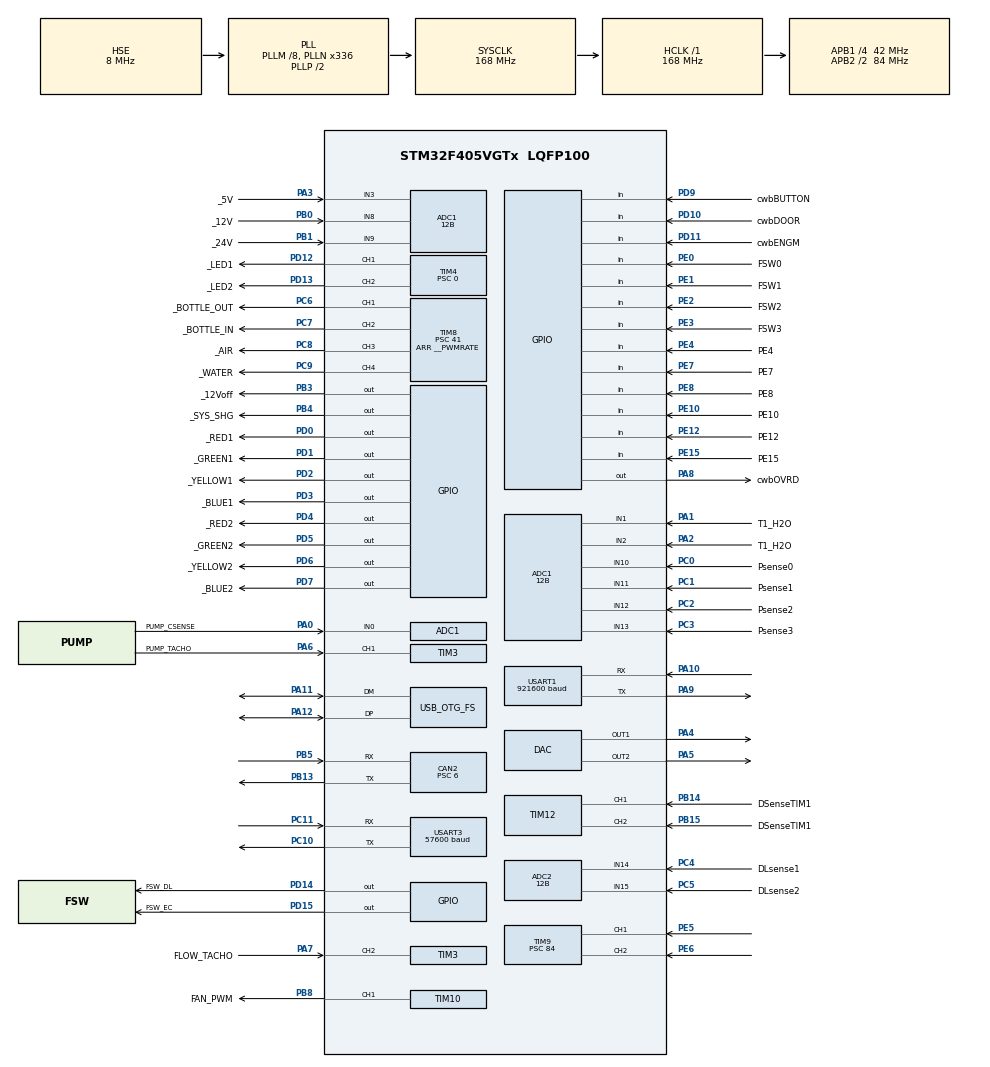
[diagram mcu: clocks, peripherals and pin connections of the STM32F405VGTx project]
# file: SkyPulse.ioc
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ADC1.Channel-0\#ChannelRegularConversion=ADC_CHANNEL_0
ADC1.Channel-1\#ChannelRegularConversion=ADC_CHANNEL_1
ADC1.Channel-2\#ChannelRegularConversion=ADC_CHANNEL_2
ADC1.Channel-3\#ChannelRegularConversion=ADC_CHANNEL_3
ADC1.Channel-4\#ChannelRegularConversion=ADC_CHANNEL_8
ADC1.Channel-5\#ChannelRegularConversion=ADC_CHANNEL_9
ADC1.Channel-6\#ChannelRegularConversion=ADC_CHANNEL_10
ADC1.Channel-7\#ChannelRegularConversion=ADC_CHANNEL_11
ADC1.Channel-8\#ChannelRegularConversion=ADC_CHANNEL_12
ADC1.Channel-9\#ChannelRegularConversion=ADC_CHANNEL_13
ADC1.ClockPrescaler=ADC_CLOCK_SYNC_PCLK_DIV4
ADC1.ContinuousConvMode=ENABLE
ADC1.DMAContinuousRequests=ENABLE
ADC1.DataAlign=ADC_DATAALIGN_RIGHT
ADC1.DiscontinuousConvMode=DISABLE
ADC1.EOCSelection=ADC_EOC_SEQ_CONV
ADC1.EnableAnalogWatchDog=false
ADC1.ExternalTrigConv=ADC_SOFTWARE_START
ADC1.ExternalTrigConvEdge=ADC_EXTERNALTRIGCONVEDGE_NONE
ADC1.InjNumberOfConversion=0
ADC1.NbrOfConversion=10
ADC1.NbrOfConversionFlag=1
ADC1.Rank-0\#ChannelRegularConversion=1
ADC1.Rank-1\#ChannelRegularConversion=2
ADC1.Rank-2\#ChannelRegularConversion=3
ADC1.Rank-3\#ChannelRegularConversion=4
ADC1.Rank-4\#ChannelRegularConversion=5
ADC1.Rank-5\#ChannelRegularConversion=6
ADC1.Rank-6\#ChannelRegularConversion=7
ADC1.Rank-7\#ChannelRegularConversion=8
ADC1.Rank-8\#ChannelRegularConversion=9
ADC1.Rank-9\#ChannelRegularConversion=10
ADC1.Resolution=ADC_RESOLUTION_12B
ADC1.SamplingTime-0\#ChannelRegularConversion=ADC_SAMPLETIME_84CYCLES
ADC1.SamplingTime-1\#ChannelRegularConversion=ADC_SAMPLETIME_84CYCLES
ADC1.SamplingTime-2\#ChannelRegularConversion=ADC_SAMPLETIME_84CYCLES
ADC1.SamplingTime-3\#ChannelRegularConversion=ADC_SAMPLETIME_84CYCLES
ADC1.SamplingTime-4\#ChannelRegularConversion=ADC_SAMPLETIME_84CYCLES
ADC1.SamplingTime-5\#ChannelRegularConversion=ADC_SAMPLETIME_84CYCLES
ADC1.SamplingTime-6\#ChannelRegularConversion=ADC_SAMPLETIME_84CYCLES
ADC1.SamplingTime-7\#ChannelRegularConversion=ADC_SAMPLETIME_84CYCLES
ADC1.SamplingTime-8\#ChannelRegularConversion=ADC_SAMPLETIME_84CYCLES
ADC1.SamplingTime-9\#ChannelRegularConversion=ADC_SAMPLETIME_84CYCLES
ADC1.ScanConvMode=ENABLE
ADC1.master=1
ADC2.Channel-0\#ChannelRegularConversion=ADC_CHANNEL_14
ADC2.Channel-1\#ChannelRegularConversion=ADC_CHANNEL_15
ADC2.ClockPrescaler=ADC_CLOCK_SYNC_PCLK_DIV4
ADC2.ContinuousConvMode=ENABLE
ADC2.DMAContinuousRequests=ENABLE
ADC2.DataAlign=ADC_DATAALIGN_RIGHT
ADC2.DiscontinuousConvMode=DISABLE
ADC2.EOCSelection=ADC_EOC_SEQ_CONV
ADC2.EnableAnalogWatchDog=false
ADC2.ExternalTrigConv=ADC_SOFTWARE_START
ADC2.ExternalTrigConvEdge=ADC_EXTERNALTRIGCONVEDGE_NONE
ADC2.InjNumberOfConversion=0
ADC2.NbrOfConversion=2
ADC2.NbrOfConversionFlag=1
ADC2.Rank-0\#ChannelRegularConversion=1
ADC2.Rank-1\#ChannelRegularConversion=2
ADC2.Resolution=ADC_RESOLUTION_12B
ADC2.SamplingTime-0\#ChannelRegularConversion=ADC_SAMPLETIME_56CYCLES
ADC2.SamplingTime-1\#ChannelRegularConversion=ADC_SAMPLETIME_56CYCLES
ADC2.ScanConvMode=ENABLE
CAN2.ABOM=ENABLE
CAN2.BS1=CAN_BS1_10TQ
CAN2.BS2=CAN_BS2_3TQ
CAN2.CalculateTimeBit=2000
CAN2.CalculateTimeQuantum=142.85714285714286
CAN2.Mode=CAN_MODE_NORMAL
CAN2.NART=ENABLE
CAN2.Prescaler=6
CAN2.SJW=CAN_SJW_4TQ
CAN2.TXFP=ENABLE
DAC.DAC_OutputBuffer2=DAC_OUTPUTBUFFER_ENABLE
DAC.DAC_Trigger=DAC_TRIGGER_T4_TRGO
Dma.ADC1.6.Direction=DMA_PERIPH_TO_MEMORY
Dma.ADC1.6.FIFOMode=DMA_FIFOMODE_DISABLE
Dma.ADC1.6.Instance=DMA2_Stream0
Dma.ADC1.6.MemDataAlignment=DMA_MDATAALIGN_HALFWORD
Dma.ADC1.6.MemInc=DMA_MINC_ENABLE
Dma.ADC1.6.Mode=DMA_CIRCULAR
Dma.ADC1.6.PeriphDataAlignment=DMA_PDATAALIGN_HALFWORD
Dma.ADC1.6.PeriphInc=DMA_PINC_DISABLE
Dma.ADC1.6.Priority=DMA_PRIORITY_LOW
Dma.ADC2.8.Direction=DMA_PERIPH_TO_MEMORY
Dma.ADC2.8.FIFOMode=DMA_FIFOMODE_DISABLE
Dma.ADC2.8.Instance=DMA2_Stream2
Dma.ADC2.8.MemDataAlignment=DMA_MDATAALIGN_HALFWORD
Dma.ADC2.8.MemInc=DMA_MINC_ENABLE
Dma.ADC2.8.Mode=DMA_CIRCULAR
Dma.ADC2.8.PeriphDataAlignment=DMA_PDATAALIGN_HALFWORD
Dma.ADC2.8.PeriphInc=DMA_PINC_DISABLE
Dma.ADC2.8.Priority=DMA_PRIORITY_LOW
Dma.DAC1.3.Direction=DMA_MEMORY_TO_PERIPH
Dma.DAC1.3.FIFOMode=DMA_FIFOMODE_ENABLE
Dma.DAC1.3.FIFOThreshold=DMA_FIFO_THRESHOLD_FULL
Dma.DAC1.3.Instance=DMA1_Stream5
Dma.DAC1.3.MemBurst=DMA_MBURST_SINGLE
Dma.DAC1.3.MemDataAlignment=DMA_MDATAALIGN_HALFWORD
Dma.DAC1.3.MemInc=DMA_MINC_ENABLE
Dma.DAC1.3.Mode=DMA_CIRCULAR
Dma.DAC1.3.PeriphBurst=DMA_PBURST_SINGLE
Dma.DAC1.3.PeriphDataAlignment=DMA_PDATAALIGN_HALFWORD
Dma.DAC1.3.PeriphInc=DMA_PINC_DISABLE
Dma.DAC1.3.Priority=DMA_PRIORITY_LOW
Dma.Request0=USART3_RX
Dma.Request1=USART3_TX
Dma.Request2=TIM4_UP
Dma.Request3=DAC1
Dma.Request4=USART1_RX
Dma.Request5=USART1_TX
Dma.Request6=ADC1
Dma.Request7=TIM8_UP
Dma.Request8=ADC2
Dma.TIM4_UP.2.Direction=DMA_MEMORY_TO_PERIPH
Dma.TIM4_UP.2.FIFOMode=DMA_FIFOMODE_ENABLE
Dma.TIM4_UP.2.FIFOThreshold=DMA_FIFO_THRESHOLD_FULL
Dma.TIM4_UP.2.Instance=DMA1_Stream6
Dma.TIM4_UP.2.MemBurst=DMA_MBURST_SINGLE
Dma.TIM4_UP.2.MemDataAlignment=DMA_MDATAALIGN_BYTE
Dma.TIM4_UP.2.MemInc=DMA_MINC_ENABLE
Dma.TIM4_UP.2.Mode=DMA_NORMAL
Dma.TIM4_UP.2.PeriphBurst=DMA_PBURST_SINGLE
Dma.TIM4_UP.2.PeriphDataAlignment=DMA_PDATAALIGN_HALFWORD
Dma.TIM4_UP.2.PeriphInc=DMA_PINC_DISABLE
Dma.TIM4_UP.2.Priority=DMA_PRIORITY_LOW
Dma.TIM8_UP.7.Direction=DMA_MEMORY_TO_PERIPH
Dma.TIM8_UP.7.FIFOMode=DMA_FIFOMODE_ENABLE
Dma.TIM8_UP.7.FIFOThreshold=DMA_FIFO_THRESHOLD_FULL
Dma.TIM8_UP.7.Instance=DMA2_Stream1
Dma.TIM8_UP.7.MemBurst=DMA_MBURST_SINGLE
Dma.TIM8_UP.7.MemDataAlignment=DMA_MDATAALIGN_WORD
Dma.TIM8_UP.7.MemInc=DMA_MINC_ENABLE
Dma.TIM8_UP.7.Mode=DMA_CIRCULAR
Dma.TIM8_UP.7.PeriphBurst=DMA_PBURST_SINGLE
Dma.TIM8_UP.7.PeriphDataAlignment=DMA_PDATAALIGN_HALFWORD
Dma.TIM8_UP.7.PeriphInc=DMA_PINC_DISABLE
Dma.TIM8_UP.7.Priority=DMA_PRIORITY_LOW
Dma.USART1_RX.4.Direction=DMA_PERIPH_TO_MEMORY
Dma.USART1_RX.4.FIFOMode=DMA_FIFOMODE_DISABLE
Dma.USART1_RX.4.Instance=DMA2_Stream5
Dma.USART1_RX.4.MemDataAlignment=DMA_MDATAALIGN_BYTE
Dma.USART1_RX.4.MemInc=DMA_MINC_ENABLE
Dma.USART1_RX.4.Mode=DMA_CIRCULAR
Dma.USART1_RX.4.PeriphDataAlignment=DMA_PDATAALIGN_BYTE
Dma.USART1_RX.4.PeriphInc=DMA_PINC_DISABLE
Dma.USART1_RX.4.Priority=DMA_PRIORITY_LOW
Dma.USART1_TX.5.Direction=DMA_MEMORY_TO_PERIPH
Dma.USART1_TX.5.FIFOMode=DMA_FIFOMODE_DISABLE
Dma.USART1_TX.5.Instance=DMA2_Stream7
Dma.USART1_TX.5.MemDataAlignment=DMA_MDATAALIGN_BYTE
Dma.USART1_TX.5.MemInc=DMA_MINC_ENABLE
Dma.USART1_TX.5.Mode=DMA_NORMAL
Dma.USART1_TX.5.PeriphDataAlignment=DMA_PDATAALIGN_BYTE
Dma.USART1_TX.5.PeriphInc=DMA_PINC_DISABLE
Dma.USART1_TX.5.Priority=DMA_PRIORITY_LOW
Dma.USART3_RX.0.Direction=DMA_PERIPH_TO_MEMORY
Dma.USART3_RX.0.FIFOMode=DMA_FIFOMODE_DISABLE
Dma.USART3_RX.0.Instance=DMA1_Stream1
Dma.USART3_RX.0.MemDataAlignment=DMA_MDATAALIGN_BYTE
Dma.USART3_RX.0.MemInc=DMA_MINC_ENABLE
Dma.USART3_RX.0.Mode=DMA_CIRCULAR
Dma.USART3_RX.0.PeriphDataAlignment=DMA_PDATAALIGN_BYTE
Dma.USART3_RX.0.PeriphInc=DMA_PINC_DISABLE
Dma.USART3_RX.0.Priority=DMA_PRIORITY_LOW
Dma.USART3_TX.1.Direction=DMA_MEMORY_TO_PERIPH
Dma.USART3_TX.1.FIFOMode=DMA_FIFOMODE_DISABLE
Dma.USART3_TX.1.Instance=DMA1_Stream3
Dma.USART3_TX.1.MemDataAlignment=DMA_MDATAALIGN_BYTE
Dma.USART3_TX.1.MemInc=DMA_MINC_ENABLE
Dma.USART3_TX.1.Mode=DMA_NORMAL
Dma.USART3_TX.1.PeriphDataAlignment=DMA_PDATAALIGN_BYTE
Dma.USART3_TX.1.PeriphInc=DMA_PINC_DISABLE
Dma.USART3_TX.1.Priority=DMA_PRIORITY_LOW
FATFS._FS_LOCK=5
FATFS._FS_RPATH=2
FATFS._USE_FIND=1
FATFS._USE_LFN=2
FATFS._VOLUMES=1
FREERTOS.HEAP_NUMBER=2
FREERTOS.Tasks01=defaultTask,0,512,StartDefaultTask,Default,NULL,Dynamic,NULL,NULL
FREERTOS.configCHECK_FOR_STACK_OVERFLOW=2
FREERTOS.configTOTAL_HEAP_SIZE=0x10000
FREERTOS.configUSE_MALLOC_FAILED_HOOK=1
IWDG.Prescaler=IWDG_PRESCALER_32
IWDG.Reload=400
Mcu.Family=STM32F4
Mcu.Name=STM32F405VGTx
Mcu.Package=LQFP100
Mcu.UserConstants=__RXLEN,128;__TXLEN,128;__CMDLEN,128;__PWMRATE,2000;__VALVES,4;__LEDS,80;__TH,94;__TL,36;__TP,130;SW_version,106
NVIC.CAN2_RX0_IRQn=true\:5\:0\:false\:false\:true\:true\:true\:true
NVIC.CAN2_SCE_IRQn=true\:5\:0\:false\:false\:true\:true\:true\:true
NVIC.CAN2_TX_IRQn=true\:5\:0\:false\:false\:true\:true\:true\:true
NVIC.DMA1_Stream1_IRQn=true\:5\:0\:false\:false\:true\:true\:true\:true
NVIC.DMA1_Stream3_IRQn=true\:5\:0\:false\:false\:true\:true\:true\:true
NVIC.DMA1_Stream5_IRQn=true\:5\:0\:false\:false\:true\:true\:false\:true
NVIC.DMA1_Stream6_IRQn=true\:5\:0\:false\:false\:true\:true\:false\:true
NVIC.DMA2_Stream0_IRQn=true\:5\:0\:false\:false\:true\:true\:false\:true
NVIC.DMA2_Stream1_IRQn=true\:5\:0\:false\:false\:true\:true\:false\:true
NVIC.DMA2_Stream2_IRQn=true\:5\:0\:false\:false\:true\:true\:false\:true
NVIC.DMA2_Stream5_IRQn=true\:5\:0\:false\:false\:true\:true\:false\:true
NVIC.DMA2_Stream7_IRQn=true\:5\:0\:false\:false\:true\:true\:true\:true
NVIC.OTG_FS_IRQn=true\:5\:0\:false\:false\:true\:true\:true\:true
NVIC.PriorityGroup=NVIC_PRIORITYGROUP_4
NVIC.TIM1_BRK_TIM9_IRQn=true\:5\:0\:false\:false\:true\:true\:true\:true
NVIC.TIM2_IRQn=true\:0\:0\:false\:false\:true\:false\:false\:true
NVIC.TIM3_IRQn=true\:5\:0\:false\:false\:true\:true\:true\:true
NVIC.TimeBase=TIM2_IRQn
NVIC.TimeBaseIP=TIM2
NVIC.USART1_IRQn=true\:5\:0\:false\:false\:true\:true\:true\:true
NVIC.USART3_IRQn=true\:5\:0\:false\:false\:true\:true\:true\:true
PA0-WKUP.GPIO_Label=PUMP_CSENSE
PA0-WKUP.Signal=ADCx_IN0
PA1.GPIO_Label=T1_H2O
PA1.Signal=ADCx_IN1
PA10.Mode=Asynchronous
PA10.Signal=USART1_RX
PA11.GPIO_PuPd=GPIO_PULLDOWN
PA11.Mode=Device_Only
PA11.Signal=USB_OTG_FS_DM
PA12.GPIO_PuPd=GPIO_PULLDOWN
PA12.Mode=Device_Only
PA12.Signal=USB_OTG_FS_DP
PA13.Mode=Serial_Wire
PA13.Signal=SYS_JTMS-SWDIO
PA14.Mode=Serial_Wire
PA14.Signal=SYS_JTCK-SWCLK
PA2.GPIO_Label=T1_H2O
PA2.Signal=ADCx_IN2
PA3.GPIO_Label=_5V
PA3.Signal=ADCx_IN3
PA4.Signal=COMP_DAC1_group
PA5.Signal=COMP_DAC2_group
PA6.GPIO_Label=PUMP_TACHO
PA6.GPIO_PuPd=GPIO_PULLUP
PA6.Signal=S_TIM3_CH1
PA7.GPIO_Label=FLOW_TACHO
PA7.GPIO_PuPd=GPIO_PULLUP
PA7.Signal=S_TIM3_CH2
PA8.GPIO_Label=cwbOVRD
PA8.GPIO_ModeDefaultOutputPP=GPIO_MODE_OUTPUT_OD
PA8.PinState=GPIO_PIN_SET
PA8.Signal=GPIO_Output
PA9.Mode=Asynchronous
PA9.Signal=USART1_TX
PB0.GPIO_Label=_12V
PB0.Signal=ADCx_IN8
PB1.GPIO_Label=_24V
PB1.Signal=ADCx_IN9
PB13.GPIO_PuPd=GPIO_PULLUP
PB13.Mode=Slave
PB13.Signal=CAN2_TX
PB14.GPIO_Label=DSenseTIM1
PB14.GPIO_PuPd=GPIO_PULLDOWN
PB14.GPIO_Speed=GPIO_SPEED_FREQ_MEDIUM
PB14.Signal=S_TIM12_CH1
PB15.GPIO_Label=DSenseTIM1
PB15.GPIO_PuPd=GPIO_PULLDOWN
PB15.GPIO_Speed=GPIO_SPEED_FREQ_MEDIUM
PB15.Signal=S_TIM12_CH2
PB3.GPIO_Label=_12Voff
PB3.Signal=GPIO_Output
PB4.GPIO_Label=_SYS_SHG
PB4.GPIO_ModeDefaultOutputPP=GPIO_MODE_OUTPUT_OD
PB4.PinState=GPIO_PIN_RESET
PB4.Signal=GPIO_Output
PB5.GPIO_PuPd=GPIO_PULLUP
PB5.Mode=Slave
PB5.Signal=CAN2_RX
PB8.GPIO_Label=FAN_PWM
PB8.GPIO_Speed=GPIO_SPEED_FREQ_HIGH
PB8.Signal=S_TIM10_CH1
PC0.GPIO_Label=Psense0
PC0.Signal=ADCx_IN10
PC1.GPIO_Label=Psense1
PC1.Signal=ADCx_IN11
PC10.Mode=Asynchronous
PC10.Signal=USART3_TX
PC11.Mode=Asynchronous
PC11.Signal=USART3_RX
PC14-OSC32_IN.Mode=LSE-External-Oscillator
PC14-OSC32_IN.Signal=RCC_OSC32_IN
PC15-OSC32_OUT.Mode=LSE-External-Oscillator
PC15-OSC32_OUT.Signal=RCC_OSC32_OUT
PC2.GPIO_Label=Psense2
PC2.Signal=ADCx_IN12
PC3.GPIO_Label=Psense3
PC3.Signal=ADCx_IN13
PC4.GPIO_Label=DLsense1
PC4.Signal=ADCx_IN14
PC5.GPIO_Label=DLsense2
PC5.GPIO_PuPd=GPIO_NOPULL
PC5.Signal=ADCx_IN15
PC6.GPIO_Label=_BOTTLE_OUT
PC6.GPIO_Speed=GPIO_SPEED_FREQ_HIGH
PC6.Signal=S_TIM8_CH1
PC7.GPIO_Label=_BOTTLE_IN
PC7.GPIO_Speed=GPIO_SPEED_FREQ_HIGH
PC7.Signal=S_TIM8_CH2
PC8.GPIO_Label=_AIR
PC8.GPIO_Speed=GPIO_SPEED_FREQ_HIGH
PC8.Signal=S_TIM8_CH3
PC9.GPIO_Label=_WATER
PC9.GPIO_Speed=GPIO_SPEED_FREQ_HIGH
PC9.Signal=S_TIM8_CH4
PD0.GPIO_Label=_RED1
PD0.GPIO_ModeDefaultOutputPP=GPIO_MODE_OUTPUT_OD
PD0.GPIO_PuPd=GPIO_NOPULL
PD0.PinState=GPIO_PIN_SET
PD0.Signal=GPIO_Output
PD1.GPIO_Label=_GREEN1
PD1.GPIO_ModeDefaultOutputPP=GPIO_MODE_OUTPUT_OD
PD1.GPIO_PuPd=GPIO_NOPULL
PD1.PinState=GPIO_PIN_SET
PD1.Signal=GPIO_Output
PD10.GPIO_Label=cwbDOOR
PD10.GPIO_PuPd=GPIO_PULLDOWN
PD10.Signal=GPIO_Input
PD11.GPIO_Label=cwbENGM
PD11.GPIO_PuPd=GPIO_PULLDOWN
PD11.Signal=GPIO_Input
PD12.GPIO_Label=_LED1
PD12.GPIO_ModeDefaultPP=GPIO_MODE_AF_OD
PD12.GPIO_PuPd=GPIO_PULLUP
PD12.GPIO_Speed=GPIO_SPEED_FREQ_VERY_HIGH
PD12.Signal=S_TIM4_CH1
PD13.GPIO_Label=_LED2
PD13.GPIO_ModeDefaultPP=GPIO_MODE_AF_OD
PD13.GPIO_PuPd=GPIO_PULLUP
PD13.GPIO_Speed=GPIO_SPEED_FREQ_VERY_HIGH
PD13.Signal=S_TIM4_CH2
PD14.GPIO_Label=FSW_DL
PD14.GPIO_ModeDefaultOutputPP=GPIO_MODE_OUTPUT_OD
PD14.PinState=GPIO_PIN_SET
PD14.Signal=GPIO_Output
PD15.GPIO_Label=FSW_EC
PD15.GPIO_ModeDefaultOutputPP=GPIO_MODE_OUTPUT_OD
PD15.PinState=GPIO_PIN_SET
PD15.Signal=GPIO_Output
PD2.GPIO_Label=_YELLOW1
PD2.GPIO_ModeDefaultOutputPP=GPIO_MODE_OUTPUT_OD
PD2.GPIO_PuPd=GPIO_NOPULL
PD2.PinState=GPIO_PIN_SET
PD2.Signal=GPIO_Output
PD3.GPIO_Label=_BLUE1
PD3.GPIO_ModeDefaultOutputPP=GPIO_MODE_OUTPUT_OD
PD3.GPIO_PuPd=GPIO_NOPULL
PD3.PinState=GPIO_PIN_SET
PD3.Signal=GPIO_Output
PD4.GPIO_Label=_RED2
PD4.GPIO_ModeDefaultOutputPP=GPIO_MODE_OUTPUT_OD
PD4.GPIO_PuPd=GPIO_NOPULL
PD4.PinState=GPIO_PIN_SET
PD4.Signal=GPIO_Output
PD5.GPIO_Label=_GREEN2
PD5.GPIO_ModeDefaultOutputPP=GPIO_MODE_OUTPUT_OD
PD5.GPIO_PuPd=GPIO_NOPULL
PD5.PinState=GPIO_PIN_SET
PD5.Signal=GPIO_Output
PD6.GPIO_Label=_YELLOW2
PD6.GPIO_ModeDefaultOutputPP=GPIO_MODE_OUTPUT_OD
PD6.GPIO_PuPd=GPIO_NOPULL
PD6.PinState=GPIO_PIN_SET
PD6.Signal=GPIO_Output
PD7.GPIO_Label=_BLUE2
PD7.GPIO_ModeDefaultOutputPP=GPIO_MODE_OUTPUT_OD
PD7.GPIO_PuPd=GPIO_NOPULL
PD7.PinState=GPIO_PIN_SET
PD7.Signal=GPIO_Output
PD9.GPIO_Label=cwbBUTTON
PD9.GPIO_PuPd=GPIO_PULLDOWN
PD9.Signal=GPIO_Input
PE0.GPIO_Label=FSW0
PE0.GPIO_PuPd=GPIO_PULLUP
PE0.Signal=GPIO_Input
PE1.GPIO_Label=FSW1
PE1.GPIO_PuPd=GPIO_PULLUP
PE1.Signal=GPIO_Input
PE10.GPIO_Label=PE10
PE10.GPIO_PuPd=GPIO_PULLUP
PE10.Signal=GPIO_Input
PE12.GPIO_Label=PE12
PE12.GPIO_PuPd=GPIO_PULLUP
PE12.Signal=GPIO_Input
PE15.GPIO_Label=PE15
PE15.GPIO_PuPd=GPIO_PULLUP
PE15.Signal=GPIO_Input
PE2.GPIO_Label=FSW2
PE2.GPIO_PuPd=GPIO_PULLUP
PE2.Signal=GPIO_Input
PE3.GPIO_Label=FSW3
PE3.GPIO_PuPd=GPIO_PULLUP
PE3.Signal=GPIO_Input
PE4.GPIO_Label=PE4
PE4.GPIO_PuPd=GPIO_PULLUP
PE4.Signal=GPIO_Input
PE5.GPIO_PuPd=GPIO_PULLUP
PE5.Signal=S_TIM9_CH1
PE6.GPIO_PuPd=GPIO_PULLUP
PE6.Signal=S_TIM9_CH2
PE7.GPIO_Label=PE7
PE7.GPIO_PuPd=GPIO_PULLUP
PE7.Signal=GPIO_Input
PE8.GPIO_Label=PE8
PE8.GPIO_PuPd=GPIO_PULLUP
PE8.Signal=GPIO_Input
PH0-OSC_IN.Mode=HSE-External-Oscillator
PH0-OSC_IN.Signal=RCC_OSC_IN
PH1-OSC_OUT.Mode=HSE-External-Oscillator
PH1-OSC_OUT.Signal=RCC_OSC_OUT
ProjectManager.HeapSize=0x6000
ProjectManager.StackSize=0x2000
ProjectManager.TargetToolchain=MDK-ARM V5
RCC.48MHZClocksFreq_Value=48000000
RCC.AHBCLKDivider=RCC_SYSCLK_DIV1
RCC.AHBFreq_Value=168000000
RCC.APB1CLKDivider=RCC_HCLK_DIV4
RCC.APB1Freq_Value=42000000
RCC.APB1TimFreq_Value=84000000
RCC.APB2CLKDivider=RCC_HCLK_DIV2
RCC.APB2Freq_Value=84000000
RCC.APB2TimFreq_Value=168000000
RCC.CortexFreq_Value=168000000
RCC.HCLKFreq_Value=168000000
RCC.HSE_VALUE=8000000
RCC.HSI_VALUE=16000000
RCC.PLLM=8
RCC.PLLN=336
RCC.PLLQ=7
RCC.RCC_RTC_Clock_Source=RCC_RTCCLKSOURCE_LSI
RCC.RCC_RTC_Clock_SourceVirtual=RCC_RTCCLKSOURCE_LSE
RCC.SYSCLKFreq_VALUE=168000000
RCC.SYSCLKSource=RCC_SYSCLKSOURCE_PLLCLK
RCC.VCOOutputFreq_Value=336000000
RTC.Date=7
RTC.Format=RTC_FORMAT_BIN
RTC.Hours=15
RTC.Minutes=30
RTC.Month=RTC_MONTH_NOVEMBER
RTC.StoreOperation=RTC_STOREOPERATION_SET
RTC.WeekDay=RTC_WEEKDAY_TUESDAY
RTC.Year=17
SH.ADCx_IN0.0=ADC1_IN0,IN0
SH.ADCx_IN1.0=ADC1_IN1,IN1
SH.ADCx_IN10.0=ADC1_IN10,IN10
SH.ADCx_IN11.0=ADC1_IN11,IN11
SH.ADCx_IN12.0=ADC1_IN12,IN12
SH.ADCx_IN13.0=ADC1_IN13,IN13
SH.ADCx_IN14.0=ADC1_IN14
SH.ADCx_IN14.1=ADC2_IN14,IN14
SH.ADCx_IN15.0=ADC1_IN15
SH.ADCx_IN15.1=ADC2_IN15,IN15
SH.ADCx_IN2.0=ADC1_IN2,IN2
SH.ADCx_IN3.0=ADC1_IN3,IN3
SH.ADCx_IN8.0=ADC1_IN8,IN8
SH.ADCx_IN9.0=ADC1_IN9,IN9
SH.COMP_DAC1_group.0=DAC_OUT1,DAC_OUT1
SH.COMP_DAC2_group.0=DAC_OUT2,DAC_OUT2
SH.S_TIM10_CH1.0=TIM10_CH1,PWM Generation1 CH1
SH.S_TIM12_CH1.0=TIM12_CH1,Input_Capture1_from_TI1
SH.S_TIM12_CH2.0=TIM12_CH2,Input_Capture2_from_TI2
SH.S_TIM3_CH1.0=TIM3_CH1,Input_Capture1_from_TI1
SH.S_TIM3_CH2.0=TIM3_CH2,Input_Capture2_from_TI2
SH.S_TIM4_CH1.0=TIM4_CH1,PWM Generation1 CH1
SH.S_TIM4_CH2.0=TIM4_CH2,PWM Generation2 CH2
SH.S_TIM8_CH1.0=TIM8_CH1,PWM Generation1 CH1
SH.S_TIM8_CH2.0=TIM8_CH2,PWM Generation2 CH2
SH.S_TIM8_CH3.0=TIM8_CH3,PWM Generation3 CH3
SH.S_TIM8_CH4.0=TIM8_CH4,PWM Generation4 CH4
SH.S_TIM9_CH1.0=TIM9_CH1,Input_Capture1_from_TI1
SH.S_TIM9_CH2.0=TIM9_CH2,Input_Capture2_from_TI2
TIM10.Channel=TIM_CHANNEL_1
TIM10.Period=__PWMRATE
TIM10.Prescaler=29
TIM10.Pulse=10
TIM12.Channel-Input_Capture1_from_TI1=TIM_CHANNEL_1
TIM12.Channel-Input_Capture2_from_TI2=TIM_CHANNEL_2
TIM12.ICFilter_CH1=15
TIM12.ICFilter_CH2=15
TIM3.Channel-Input_Capture1_from_TI1=TIM_CHANNEL_1
TIM3.Channel-Input_Capture2_from_TI2=TIM_CHANNEL_2
TIM3.ICFilter_CH1=15
TIM3.ICFilter_CH2=15
TIM3.ICPolarity_CH1=TIM_INPUTCHANNELPOLARITY_BOTHEDGE
TIM3.ICPolarity_CH2=TIM_INPUTCHANNELPOLARITY_BOTHEDGE
TIM3.Prescaler=84
TIM4.Channel-PWM\ Generation1\ CH1=TIM_CHANNEL_1
TIM4.Channel-PWM\ Generation2\ CH2=TIM_CHANNEL_2
TIM4.CounterMode=TIM_COUNTERMODE_UP
TIM4.Period=__TP
TIM4.Prescaler=0
TIM4.TIM_MasterOutputTrigger=TIM_TRGO_UPDATE
TIM4.TIM_MasterSlaveMode=TIM_MASTERSLAVEMODE_ENABLE
TIM8.Channel-PWM\ Generation1\ CH1=TIM_CHANNEL_1
TIM8.Channel-PWM\ Generation2\ CH2=TIM_CHANNEL_2
TIM8.Channel-PWM\ Generation3\ CH3=TIM_CHANNEL_3
TIM8.Channel-PWM\ Generation4\ CH4=TIM_CHANNEL_4
TIM8.CounterMode=TIM_COUNTERMODE_CENTERALIGNED1
TIM8.Period=__PWMRATE
TIM8.Prescaler=41
TIM8.TIM_MasterOutputTrigger=TIM_TRGO_UPDATE
TIM8.TIM_MasterSlaveMode=TIM_MASTERSLAVEMODE_ENABLE
TIM9.Channel-Input_Capture1_from_TI1=TIM_CHANNEL_1
TIM9.Channel-Input_Capture2_from_TI2=TIM_CHANNEL_2
TIM9.ICFilter_CH1=15
TIM9.ICFilter_CH2=15
TIM9.ICPolarity_CH1=TIM_INPUTCHANNELPOLARITY_BOTHEDGE
TIM9.ICPolarity_CH2=TIM_INPUTCHANNELPOLARITY_BOTHEDGE
TIM9.Period=0xffff
TIM9.Prescaler=84
USART1.BaudRate=921600
USART1.HwFlowCtl-Asynchronous=UART_HWCONTROL_NONE
USART1.VirtualMode=VM_ASYNC
USART3.BaudRate=57600
USART3.VirtualMode=VM_ASYNC
USB_DEVICE.CLASS_NAME_FS=CDC
USB_DEVICE.VirtualMode-CDC_FS=Cdc
USB_DEVICE.VirtualModeFS=Cdc_FS
USB_OTG_FS.VirtualMode=Device_Only
USB_OTG_FS.dev_endpoints=4
USB_OTG_FS.vbus_sensing_enable=DISABLE
VP_CRC_VS_CRC.Mode=CRC_Activate
VP_FATFS_VS_Generic.Mode=User_defined
VP_FREERTOS_VS_CMSIS_V1.Mode=CMSIS_V1
VP_IWDG_VS_IWDG.Mode=IWDG_Activate
VP_RTC_VS_RTC_Activate.Mode=RTC_Enabled
VP_RTC_VS_RTC_Calendar.Mode=RTC_Calendar
VP_SYS_VS_tim2.Mode=TIM2
VP_TIM10_VS_ClockSourceINT.Mode=Enable_Timer
VP_TIM12_VS_ClockSourceINT.Mode=Internal
VP_TIM3_VS_ClockSourceINT.Mode=Internal
VP_TIM9_VS_ClockSourceINT.Mode=Internal
VP_USB_DEVICE_VS_USB_DEVICE_CDC_FS.Mode=CDC_FS
board=SkyPulse

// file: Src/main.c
/* USER CODE BEGIN Header */
/**
  ******************************************************************************
  * @file           : main.c
  * @brief          : Main program body
  ******************************************************************************
  * This notice applies to any and all portions of this file
  * that are not between comment pairs USER CODE BEGIN and
  * USER CODE END. Other portions of this file, whether
  * inserted by the user or by software development tools
  * are owned by their respective copyright owners.
  *
  * Copyright (c) 2019 STMicroelectronics International N.V.
  * All rights reserved.
  *
  * Redistribution and use in source and binary forms, with or without
  * modification, are permitted, provided that the following conditions are met:
  *
  * 1. Redistribution of source code must retain the above copyright notice,
  *    this list of conditions and the following disclaimer.
  * 2. Redistributions in binary form must reproduce the above copyright notice,
  *    this list of conditions and the following disclaimer in the documentation
  *    and/or other materials provided with the distribution.
  * 3. Neither the name of STMicroelectronics nor the names of other
  *    contributors to this software may be used to endorse or promote products
  *    derived from this software without specific written permission.
  * 4. This software, including modifications and/or derivative works of this
  *    software, must execute solely and exclusively on microcontroller or
  *    microprocessor devices manufactured by or for STMicroelectronics.
  * 5. Redistribution and use of this software other than as permitted under
  *    this license is void and will automatically terminate your rights under
  *    this license.
  *
  * THIS SOFTWARE IS PROVIDED BY STMICROELECTRONICS AND CONTRIBUTORS "AS IS"
  * AND ANY EXPRESS, IMPLIED OR STATUTORY WARRANTIES, INCLUDING, BUT NOT
  * LIMITED TO, THE IMPLIED WARRANTIES OF MERCHANTABILITY, FITNESS FOR A
  * PARTICULAR PURPOSE AND NON-INFRINGEMENT OF THIRD PARTY INTELLECTUAL PROPERTY
  * RIGHTS ARE DISCLAIMED TO THE FULLEST EXTENT PERMITTED BY LAW. IN NO EVENT
  * SHALL STMICROELECTRONICS OR CONTRIBUTORS BE LIABLE FOR ANY DIRECT, INDIRECT,
  * INCIDENTAL, SPECIAL, EXEMPLARY, OR CONSEQUENTIAL DAMAGES (INCLUDING, BUT NOT
  * LIMITED TO, PROCUREMENT OF SUBSTITUTE GOODS OR SERVICES; LOSS OF USE, DATA,
  * OR PROFITS; OR BUSINESS INTERRUPTION) HOWEVER CAUSED AND ON ANY THEORY OF
  * LIABILITY, WHETHER IN CONTRACT, STRICT LIABILITY, OR TORT (INCLUDING
  * NEGLIGENCE OR OTHERWISE) ARISING IN ANY WAY OUT OF THE USE OF THIS SOFTWARE,
  * EVEN IF ADVISED OF THE POSSIBILITY OF SUCH DAMAGE.
  *
  ******************************************************************************
  */
/* USER CODE END Header */
#include "main.h"
#include "cmsis_os.h"
#include "fatfs.h"
#include "usb_device.h"

/* USER CODE BEGIN Includes */
#include "misc.h"
/* USER CODE END Includes */

ADC_HandleTypeDef hadc1;
ADC_HandleTypeDef hadc2;
DMA_HandleTypeDef hdma_adc1;
DMA_HandleTypeDef hdma_adc2;

CAN_HandleTypeDef hcan2;

CRC_HandleTypeDef hcrc;

DAC_HandleTypeDef hdac;
DMA_HandleTypeDef hdma_dac1;

IWDG_HandleTypeDef hiwdg;

RTC_HandleTypeDef hrtc;

TIM_HandleTypeDef htim3;
TIM_HandleTypeDef htim4;
TIM_HandleTypeDef htim8;
TIM_HandleTypeDef htim9;
TIM_HandleTypeDef htim10;
TIM_HandleTypeDef htim12;
DMA_HandleTypeDef hdma_tim4_up;
DMA_HandleTypeDef hdma_tim8_up;

UART_HandleTypeDef huart1;
UART_HandleTypeDef huart3;
DMA_HandleTypeDef hdma_usart1_rx;
DMA_HandleTypeDef hdma_usart1_tx;
DMA_HandleTypeDef hdma_usart3_rx;
DMA_HandleTypeDef hdma_usart3_tx;

osThreadId defaultTaskHandle;
/* USER CODE BEGIN PV */
/* Private variables ---------------------------------------------------------*/
/* USER CODE END PV */

void SystemClock_Config(void);
static void MX_GPIO_Init(void);
static void MX_DMA_Init(void);
static void MX_ADC1_Init(void);
static void MX_DAC_Init(void);
static void MX_USART1_UART_Init(void);
static void MX_USART3_UART_Init(void);
static void MX_CAN2_Init(void);
static void MX_TIM10_Init(void);
static void MX_TIM9_Init(void);
static void MX_TIM3_Init(void);
static void MX_TIM8_Init(void);
static void MX_TIM4_Init(void);
static void MX_RTC_Init(void);
static void MX_ADC2_Init(void);
static void MX_IWDG_Init(void);
static void MX_CRC_Init(void);
static void MX_TIM12_Init(void);
void StartDefaultTask(void const * argument);

/* USER CODE BEGIN PFP */
/* Private function prototypes -----------------------------------------------*/
void makeIoc(void);																										// main app. C++ relay object
/* USER CODE END PFP */

/* USER CODE BEGIN 0 */
uint32_t	pumpTacho, fanTacho, flowTacho, valve_timeout[__VALVES];	// DMA memory registers..
uint16_t	pump_drive, fan_drive, valve_drive[__VALVES], led_drive[__LEDS*24+2];
_io				*canBuffer=NULL;
hwVersion	hw;
/* USER CODE END 0 */

int main(void)
{

  /* MCU Configuration--------------------------------------------------------*/

  /* Reset of all peripherals, Initializes the Flash interface and the Systick. */
  HAL_Init();

  /* Configure the system clock */
  SystemClock_Config();

  /* Initialize all configured peripherals */
  MX_GPIO_Init();
  MX_DMA_Init();
  MX_FATFS_Init();
  MX_ADC1_Init();
  MX_DAC_Init();
  MX_USART1_UART_Init();
  MX_USART3_UART_Init();
  MX_CAN2_Init();
  MX_TIM10_Init();
  MX_TIM9_Init();
  MX_TIM3_Init();
  MX_TIM8_Init();
  MX_TIM4_Init();
  MX_RTC_Init();
  MX_ADC2_Init();
  MX_IWDG_Init();
  MX_CRC_Init();
  MX_TIM12_Init();
  /* USER CODE BEGIN 2 */

	hw=(hwVersion)((~(HAL_GPIO_ReadPin(PE15_GPIO_Port, PE15_Pin) +
			2*(HAL_GPIO_ReadPin(PE12_GPIO_Port, PE12_Pin) +
				2*(HAL_GPIO_ReadPin(PE10_GPIO_Port, PE10_Pin) +
					2*(HAL_GPIO_ReadPin(PE8_GPIO_Port, PE8_Pin) +
						2*HAL_GPIO_ReadPin(PE7_GPIO_Port, PE7_Pin))))) + 1) & 0x1f);

	HAL_TIM_IC_Start_IT(&htim3,TIM_CHANNEL_1);
	HAL_TIM_IC_Start_IT(&htim3,TIM_CHANNEL_2);
	HAL_TIM_IC_Start_IT(&htim9,TIM_CHANNEL_1);
	HAL_TIM_IC_Start_IT(&htim9,TIM_CHANNEL_2);
	HAL_TIM_PWM_Start(&htim10,TIM_CHANNEL_1);

	HAL_TIM_PWM_Start(&htim8,TIM_CHANNEL_1);
	HAL_TIM_PWM_Start(&htim8,TIM_CHANNEL_2);
	HAL_TIM_PWM_Start(&htim8,TIM_CHANNEL_3);
	HAL_TIM_PWM_Start(&htim8,TIM_CHANNEL_4);

	HAL_TIM_DMABurst_WriteStart(&htim8,TIM_DMABASE_CCR1,TIM_DMA_UPDATE,(uint32_t *)valve_drive,TIM_DMABURSTLENGTH_4TRANSFERS);
	HAL_DAC_Start_DMA(&hdac,DAC_CHANNEL_1,(uint32_t *)&pump_drive,1,DAC_ALIGN_12B_R);
	HAL_DAC_Start(&hdac,DAC_CHANNEL_2);

	HAL_TIM_PWM_Start(&htim4,TIM_CHANNEL_1);
	HAL_TIM_PWM_Start(&htim4,TIM_CHANNEL_2);
	HAL_TIM_DMABurst_WriteStart(&htim4,TIM_DMABASE_CCR1,TIM_DMA_UPDATE,(uint32_t *)led_drive,TIM_DMABURSTLENGTH_2TRANSFERS);
  /* USER CODE END 2 */

  /* Create the thread(s) */
  /* definition and creation of defaultTask */
  osThreadDef(defaultTask, StartDefaultTask, osPriorityNormal, 0, 512);
  defaultTaskHandle = osThreadCreate(osThread(defaultTask), NULL);

  /* Start scheduler */
  osKernelStart();

  /* We should never get here as control is now taken by the scheduler */
  /* Infinite loop */
  while (1)
  {

  }
}

void SystemClock_Config(void)
{
  RCC_OscInitTypeDef RCC_OscInitStruct = {0};
  RCC_ClkInitTypeDef RCC_ClkInitStruct = {0};
  RCC_PeriphCLKInitTypeDef PeriphClkInitStruct = {0};

  /** Configure the main internal regulator output voltage
  */
  __HAL_RCC_PWR_CLK_ENABLE();
  __HAL_PWR_VOLTAGESCALING_CONFIG(PWR_REGULATOR_VOLTAGE_SCALE1);
  /** Initializes the RCC Oscillators according to the specified parameters
  * in the RCC_OscInitTypeDef structure.
  */
  RCC_OscInitStruct.OscillatorType = RCC_OSCILLATORTYPE_LSI|RCC_OSCILLATORTYPE_HSE;
  RCC_OscInitStruct.HSEState = RCC_HSE_ON;
  RCC_OscInitStruct.LSIState = RCC_LSI_ON;
  RCC_OscInitStruct.PLL.PLLState = RCC_PLL_ON;
  RCC_OscInitStruct.PLL.PLLSource = RCC_PLLSOURCE_HSE;
  RCC_OscInitStruct.PLL.PLLM = 8;
  RCC_OscInitStruct.PLL.PLLN = 336;
  RCC_OscInitStruct.PLL.PLLP = RCC_PLLP_DIV2;
  RCC_OscInitStruct.PLL.PLLQ = 7;
  if (HAL_RCC_OscConfig(&RCC_OscInitStruct) != HAL_OK)
  {
    Error_Handler();
  }
  /** Initializes the CPU, AHB and APB buses clocks
  */
  RCC_ClkInitStruct.ClockType = RCC_CLOCKTYPE_HCLK|RCC_CLOCKTYPE_SYSCLK
                              |RCC_CLOCKTYPE_PCLK1|RCC_CLOCKTYPE_PCLK2;
  RCC_ClkInitStruct.SYSCLKSource = RCC_SYSCLKSOURCE_PLLCLK;
  RCC_ClkInitStruct.AHBCLKDivider = RCC_SYSCLK_DIV1;
  RCC_ClkInitStruct.APB1CLKDivider = RCC_HCLK_DIV4;
  RCC_ClkInitStruct.APB2CLKDivider = RCC_HCLK_DIV2;

  if (HAL_RCC_ClockConfig(&RCC_ClkInitStruct, FLASH_LATENCY_5) != HAL_OK)
  {
    Error_Handler();
  }
  PeriphClkInitStruct.PeriphClockSelection = RCC_PERIPHCLK_RTC;
  PeriphClkInitStruct.RTCClockSelection = RCC_RTCCLKSOURCE_LSI;
  if (HAL_RCCEx_PeriphCLKConfig(&PeriphClkInitStruct) != HAL_OK)
  {
    Error_Handler();
  }
}

static void MX_ADC1_Init(void)
{

  ADC_ChannelConfTypeDef sConfig = {0};

  /** Configure the global features of the ADC (Clock, Resolution, Data Alignment and number of conversion)
  */
  hadc1.Instance = ADC1;
  hadc1.Init.ClockPrescaler = ADC_CLOCK_SYNC_PCLK_DIV4;
  hadc1.Init.Resolution = ADC_RESOLUTION_12B;
  hadc1.Init.ScanConvMode = ENABLE;
  hadc1.Init.ContinuousConvMode = ENABLE;
  hadc1.Init.DiscontinuousConvMode = DISABLE;
  hadc1.Init.ExternalTrigConvEdge = ADC_EXTERNALTRIGCONVEDGE_NONE;
  hadc1.Init.ExternalTrigConv = ADC_SOFTWARE_START;
  hadc1.Init.DataAlign = ADC_DATAALIGN_RIGHT;
  hadc1.Init.NbrOfConversion = 10;
  hadc1.Init.DMAContinuousRequests = ENABLE;
  hadc1.Init.EOCSelection = ADC_EOC_SEQ_CONV;
  if (HAL_ADC_Init(&hadc1) != HAL_OK)
  {
    Error_Handler();
  }
  /** Configure for the selected ADC regular channel its corresponding rank in the sequencer and its sample time.
  */
  sConfig.Channel = ADC_CHANNEL_0;
  sConfig.Rank = 1;
  sConfig.SamplingTime = ADC_SAMPLETIME_84CYCLES;
  if (HAL_ADC_ConfigChannel(&hadc1, &sConfig) != HAL_OK)
  {
    Error_Handler();
  }
  /** Configure for the selected ADC regular channel its corresponding rank in the sequencer and its sample time.
  */
  sConfig.Channel = ADC_CHANNEL_1;
  sConfig.Rank = 2;
  if (HAL_ADC_ConfigChannel(&hadc1, &sConfig) != HAL_OK)
  {
    Error_Handler();
  }
  /** Configure for the selected ADC regular channel its corresponding rank in the sequencer and its sample time.
  */
  sConfig.Channel = ADC_CHANNEL_2;
  sConfig.Rank = 3;
  if (HAL_ADC_ConfigChannel(&hadc1, &sConfig) != HAL_OK)
  {
    Error_Handler();
  }
  /** Configure for the selected ADC regular channel its corresponding rank in the sequencer and its sample time.
  */
  sConfig.Channel = ADC_CHANNEL_3;
  sConfig.Rank = 4;
  if (HAL_ADC_ConfigChannel(&hadc1, &sConfig) != HAL_OK)
  {
    Error_Handler();
  }
  /** Configure for the selected ADC regular channel its corresponding rank in the sequencer and its sample time.
  */
  sConfig.Channel = ADC_CHANNEL_8;
  sConfig.Rank = 5;
  if (HAL_ADC_ConfigChannel(&hadc1, &sConfig) != HAL_OK)
  {
    Error_Handler();
  }
  /** Configure for the selected ADC regular channel its corresponding rank in the sequencer and its sample time.
  */
  sConfig.Channel = ADC_CHANNEL_9;
  sConfig.Rank = 6;
  if (HAL_ADC_ConfigChannel(&hadc1, &sConfig) != HAL_OK)
  {
    Error_Handler();
  }
  /** Configure for the selected ADC regular channel its corresponding rank in the sequencer and its sample time.
  */
  sConfig.Channel = ADC_CHANNEL_10;
  sConfig.Rank = 7;
  if (HAL_ADC_ConfigChannel(&hadc1, &sConfig) != HAL_OK)
  {
    Error_Handler();
  }
  /** Configure for the selected ADC regular channel its corresponding rank in the sequencer and its sample time.
  */
  sConfig.Channel = ADC_CHANNEL_11;
  sConfig.Rank = 8;
  if (HAL_ADC_ConfigChannel(&hadc1, &sConfig) != HAL_OK)
  {
    Error_Handler();
  }
  /** Configure for the selected ADC regular channel its corresponding rank in the sequencer and its sample time.
  */
  sConfig.Channel = ADC_CHANNEL_12;
  sConfig.Rank = 9;
  if (HAL_ADC_ConfigChannel(&hadc1, &sConfig) != HAL_OK)
  {
    Error_Handler();
  }
  /** Configure for the selected ADC regular channel its corresponding rank in the sequencer and its sample time.
  */
  sConfig.Channel = ADC_CHANNEL_13;
  sConfig.Rank = 10;
  if (HAL_ADC_ConfigChannel(&hadc1, &sConfig) != HAL_OK)
  {
    Error_Handler();
  }

}

static void MX_ADC2_Init(void)
{

  ADC_ChannelConfTypeDef sConfig = {0};

  /** Configure the global features of the ADC (Clock, Resolution, Data Alignment and number of conversion)
  */
  hadc2.Instance = ADC2;
  hadc2.Init.ClockPrescaler = ADC_CLOCK_SYNC_PCLK_DIV4;
  hadc2.Init.Resolution = ADC_RESOLUTION_12B;
  hadc2.Init.ScanConvMode = ENABLE;
  hadc2.Init.ContinuousConvMode = ENABLE;
  hadc2.Init.DiscontinuousConvMode = DISABLE;
  hadc2.Init.ExternalTrigConvEdge = ADC_EXTERNALTRIGCONVEDGE_NONE;
  hadc2.Init.ExternalTrigConv = ADC_SOFTWARE_START;
  hadc2.Init.DataAlign = ADC_DATAALIGN_RIGHT;
  hadc2.Init.NbrOfConversion = 2;
  hadc2.Init.DMAContinuousRequests = ENABLE;
  hadc2.Init.EOCSelection = ADC_EOC_SEQ_CONV;
  if (HAL_ADC_Init(&hadc2) != HAL_OK)
  {
    Error_Handler();
  }
  /** Configure for the selected ADC regular channel its corresponding rank in the sequencer and its sample time.
  */
  sConfig.Channel = ADC_CHANNEL_14;
  sConfig.Rank = 1;
  sConfig.SamplingTime = ADC_SAMPLETIME_56CYCLES;
  if (HAL_ADC_ConfigChannel(&hadc2, &sConfig) != HAL_OK)
  {
    Error_Handler();
  }
  /** Configure for the selected ADC regular channel its corresponding rank in the sequencer and its sample time.
  */
  sConfig.Channel = ADC_CHANNEL_15;
  sConfig.Rank = 2;
  if (HAL_ADC_ConfigChannel(&hadc2, &sConfig) != HAL_OK)
  {
    Error_Handler();
  }

}

static void MX_CAN2_Init(void)
{

  hcan2.Instance = CAN2;
  hcan2.Init.Prescaler = 6;
  hcan2.Init.Mode = CAN_MODE_NORMAL;
  hcan2.Init.SyncJumpWidth = CAN_SJW_4TQ;
  hcan2.Init.TimeSeg1 = CAN_BS1_10TQ;
  hcan2.Init.TimeSeg2 = CAN_BS2_3TQ;
  hcan2.Init.TimeTriggeredMode = DISABLE;
  hcan2.Init.AutoBusOff = ENABLE;
  hcan2.Init.AutoWakeUp = DISABLE;
  hcan2.Init.AutoRetransmission = ENABLE;
  hcan2.Init.ReceiveFifoLocked = DISABLE;
  hcan2.Init.TransmitFifoPriority = ENABLE;
  if (HAL_CAN_Init(&hcan2) != HAL_OK)
  {
    Error_Handler();
  }

}

static void MX_CRC_Init(void)
{

  hcrc.Instance = CRC;
  if (HAL_CRC_Init(&hcrc) != HAL_OK)
  {
    Error_Handler();
  }

}

static void MX_DAC_Init(void)
{

  DAC_ChannelConfTypeDef sConfig = {0};

  /** DAC Initialization
  */
  hdac.Instance = DAC;
  if (HAL_DAC_Init(&hdac) != HAL_OK)
  {
    Error_Handler();
  }
  /** DAC channel OUT1 config
  */
  sConfig.DAC_Trigger = DAC_TRIGGER_T4_TRGO;
  sConfig.DAC_OutputBuffer = DAC_OUTPUTBUFFER_ENABLE;
  if (HAL_DAC_ConfigChannel(&hdac, &sConfig, DAC_CHANNEL_1) != HAL_OK)
  {
    Error_Handler();
  }
  /** DAC channel OUT2 config
  */
  sConfig.DAC_Trigger = DAC_TRIGGER_NONE;
  if (HAL_DAC_ConfigChannel(&hdac, &sConfig, DAC_CHANNEL_2) != HAL_OK)
  {
    Error_Handler();
  }

}

static void MX_IWDG_Init(void)
{

  hiwdg.Instance = IWDG;
  hiwdg.Init.Prescaler = IWDG_PRESCALER_32;
  hiwdg.Init.Reload = 400;
  if (HAL_IWDG_Init(&hiwdg) != HAL_OK)
  {
    Error_Handler();
  }

}

static void MX_RTC_Init(void)
{

  RTC_TimeTypeDef sTime = {0};
  RTC_DateTypeDef sDate = {0};

  /** Initialize RTC Only
  */
  hrtc.Instance = RTC;
  hrtc.Init.HourFormat = RTC_HOURFORMAT_24;
  hrtc.Init.AsynchPrediv = 127;
  hrtc.Init.SynchPrediv = 255;
  hrtc.Init.OutPut = RTC_OUTPUT_DISABLE;
  hrtc.Init.OutPutPolarity = RTC_OUTPUT_POLARITY_HIGH;
  hrtc.Init.OutPutType = RTC_OUTPUT_TYPE_OPENDRAIN;
  if (HAL_RTC_Init(&hrtc) != HAL_OK)
  {
    Error_Handler();
  }

  /** Initialize RTC and set the Time and Date
  */
  sTime.Hours = 15;
  sTime.Minutes = 30;
  sTime.Seconds = 0;
  sTime.DayLightSaving = RTC_DAYLIGHTSAVING_NONE;
  sTime.StoreOperation = RTC_STOREOPERATION_SET;
  if (HAL_RTC_SetTime(&hrtc, &sTime, RTC_FORMAT_BIN) != HAL_OK)
  {
    Error_Handler();
  }
  sDate.WeekDay = RTC_WEEKDAY_TUESDAY;
  sDate.Month = RTC_MONTH_NOVEMBER;
  sDate.Date = 7;
  sDate.Year = 17;

  if (HAL_RTC_SetDate(&hrtc, &sDate, RTC_FORMAT_BIN) != HAL_OK)
  {
    Error_Handler();
  }

}

static void MX_TIM3_Init(void)
{

  TIM_ClockConfigTypeDef sClockSourceConfig = {0};
  TIM_MasterConfigTypeDef sMasterConfig = {0};
  TIM_IC_InitTypeDef sConfigIC = {0};

  htim3.Instance = TIM3;
  htim3.Init.Prescaler = 84;
  htim3.Init.CounterMode = TIM_COUNTERMODE_UP;
  htim3.Init.Period = 65535;
  htim3.Init.ClockDivision = TIM_CLOCKDIVISION_DIV1;
  htim3.Init.AutoReloadPreload = TIM_AUTORELOAD_PRELOAD_DISABLE;
  if (HAL_TIM_Base_Init(&htim3) != HAL_OK)
  {
    Error_Handler();
  }
  sClockSourceConfig.ClockSource = TIM_CLOCKSOURCE_INTERNAL;
  if (HAL_TIM_ConfigClockSource(&htim3, &sClockSourceConfig) != HAL_OK)
  {
    Error_Handler();
  }
  if (HAL_TIM_IC_Init(&htim3) != HAL_OK)
  {
    Error_Handler();
  }
  sMasterConfig.MasterOutputTrigger = TIM_TRGO_RESET;
  sMasterConfig.MasterSlaveMode = TIM_MASTERSLAVEMODE_DISABLE;
  if (HAL_TIMEx_MasterConfigSynchronization(&htim3, &sMasterConfig) != HAL_OK)
  {
    Error_Handler();
  }
  sConfigIC.ICPolarity = TIM_INPUTCHANNELPOLARITY_BOTHEDGE;
  sConfigIC.ICSelection = TIM_ICSELECTION_DIRECTTI;
  sConfigIC.ICPrescaler = TIM_ICPSC_DIV1;
  sConfigIC.ICFilter = 15;
  if (HAL_TIM_IC_ConfigChannel(&htim3, &sConfigIC, TIM_CHANNEL_1) != HAL_OK)
  {
    Error_Handler();
  }
  if (HAL_TIM_IC_ConfigChannel(&htim3, &sConfigIC, TIM_CHANNEL_2) != HAL_OK)
  {
    Error_Handler();
  }

}

static void MX_TIM4_Init(void)
{

  TIM_MasterConfigTypeDef sMasterConfig = {0};
  TIM_OC_InitTypeDef sConfigOC = {0};

  htim4.Instance = TIM4;
  htim4.Init.Prescaler = 0;
  htim4.Init.CounterMode = TIM_COUNTERMODE_UP;
  htim4.Init.Period = __TP;
  htim4.Init.ClockDivision = TIM_CLOCKDIVISION_DIV1;
  htim4.Init.AutoReloadPreload = TIM_AUTORELOAD_PRELOAD_DISABLE;
  if (HAL_TIM_PWM_Init(&htim4) != HAL_OK)
  {
    Error_Handler();
  }
  sMasterConfig.MasterOutputTrigger = TIM_TRGO_UPDATE;
  sMasterConfig.MasterSlaveMode = TIM_MASTERSLAVEMODE_ENABLE;
  if (HAL_TIMEx_MasterConfigSynchronization(&htim4, &sMasterConfig) != HAL_OK)
  {
    Error_Handler();
  }
  sConfigOC.OCMode = TIM_OCMODE_PWM1;
  sConfigOC.Pulse = 0;
  sConfigOC.OCPolarity = TIM_OCPOLARITY_HIGH;
  sConfigOC.OCFastMode = TIM_OCFAST_DISABLE;
  if (HAL_TIM_PWM_ConfigChannel(&htim4, &sConfigOC, TIM_CHANNEL_1) != HAL_OK)
  {
    Error_Handler();
  }
  if (HAL_TIM_PWM_ConfigChannel(&htim4, &sConfigOC, TIM_CHANNEL_2) != HAL_OK)
  {
    Error_Handler();
  }
  HAL_TIM_MspPostInit(&htim4);

}

static void MX_TIM8_Init(void)
{

  TIM_MasterConfigTypeDef sMasterConfig = {0};
  TIM_OC_InitTypeDef sConfigOC = {0};
  TIM_BreakDeadTimeConfigTypeDef sBreakDeadTimeConfig = {0};

  htim8.Instance = TIM8;
  htim8.Init.Prescaler = 41;
  htim8.Init.CounterMode = TIM_COUNTERMODE_CENTERALIGNED1;
  htim8.Init.Period = __PWMRATE;
  htim8.Init.ClockDivision = TIM_CLOCKDIVISION_DIV1;
  htim8.Init.RepetitionCounter = 0;
  htim8.Init.AutoReloadPreload = TIM_AUTORELOAD_PRELOAD_DISABLE;
  if (HAL_TIM_PWM_Init(&htim8) != HAL_OK)
  {
    Error_Handler();
  }
  sMasterConfig.MasterOutputTrigger = TIM_TRGO_UPDATE;
  sMasterConfig.MasterSlaveMode = TIM_MASTERSLAVEMODE_ENABLE;
  if (HAL_TIMEx_MasterConfigSynchronization(&htim8, &sMasterConfig) != HAL_OK)
  {
    Error_Handler();
  }
  sConfigOC.OCMode = TIM_OCMODE_PWM1;
  sConfigOC.Pulse = 0;
  sConfigOC.OCPolarity = TIM_OCPOLARITY_HIGH;
  sConfigOC.OCNPolarity = TIM_OCNPOLARITY_HIGH;
  sConfigOC.OCFastMode = TIM_OCFAST_DISABLE;
  sConfigOC.OCIdleState = TIM_OCIDLESTATE_RESET;
  sConfigOC.OCNIdleState = TIM_OCNIDLESTATE_RESET;
  if (HAL_TIM_PWM_ConfigChannel(&htim8, &sConfigOC, TIM_CHANNEL_1) != HAL_OK)
  {
    Error_Handler();
  }
  if (HAL_TIM_PWM_ConfigChannel(&htim8, &sConfigOC, TIM_CHANNEL_2) != HAL_OK)
  {
    Error_Handler();
  }
  if (HAL_TIM_PWM_ConfigChannel(&htim8, &sConfigOC, TIM_CHANNEL_3) != HAL_OK)
  {
    Error_Handler();
  }
  if (HAL_TIM_PWM_ConfigChannel(&htim8, &sConfigOC, TIM_CHANNEL_4) != HAL_OK)
  {
    Error_Handler();
  }
  sBreakDeadTimeConfig.OffStateRunMode = TIM_OSSR_DISABLE;
  sBreakDeadTimeConfig.OffStateIDLEMode = TIM_OSSI_DISABLE;
  sBreakDeadTimeConfig.LockLevel = TIM_LOCKLEVEL_OFF;
  sBreakDeadTimeConfig.DeadTime = 0;
  sBreakDeadTimeConfig.BreakState = TIM_BREAK_DISABLE;
  sBreakDeadTimeConfig.BreakPolarity = TIM_BREAKPOLARITY_HIGH;
  sBreakDeadTimeConfig.AutomaticOutput = TIM_AUTOMATICOUTPUT_DISABLE;
  if (HAL_TIMEx_ConfigBreakDeadTime(&htim8, &sBreakDeadTimeConfig) != HAL_OK)
  {
    Error_Handler();
  }
  HAL_TIM_MspPostInit(&htim8);

}

static void MX_TIM9_Init(void)
{

  TIM_ClockConfigTypeDef sClockSourceConfig = {0};
  TIM_IC_InitTypeDef sConfigIC = {0};

  htim9.Instance = TIM9;
  htim9.Init.Prescaler = 84;
  htim9.Init.CounterMode = TIM_COUNTERMODE_UP;
  htim9.Init.Period = 0xffff;
  htim9.Init.ClockDivision = TIM_CLOCKDIVISION_DIV1;
  htim9.Init.AutoReloadPreload = TIM_AUTORELOAD_PRELOAD_DISABLE;
  if (HAL_TIM_Base_Init(&htim9) != HAL_OK)
  {
    Error_Handler();
  }
  sClockSourceConfig.ClockSource = TIM_CLOCKSOURCE_INTERNAL;
  if (HAL_TIM_ConfigClockSource(&htim9, &sClockSourceConfig) != HAL_OK)
  {
    Error_Handler();
  }
  if (HAL_TIM_IC_Init(&htim9) != HAL_OK)
  {
    Error_Handler();
  }
  sConfigIC.ICPolarity = TIM_INPUTCHANNELPOLARITY_BOTHEDGE;
  sConfigIC.ICSelection = TIM_ICSELECTION_DIRECTTI;
  sConfigIC.ICPrescaler = TIM_ICPSC_DIV1;
  sConfigIC.ICFilter = 15;
  if (HAL_TIM_IC_ConfigChannel(&htim9, &sConfigIC, TIM_CHANNEL_1) != HAL_OK)
  {
    Error_Handler();
  }
  if (HAL_TIM_IC_ConfigChannel(&htim9, &sConfigIC, TIM_CHANNEL_2) != HAL_OK)
  {
    Error_Handler();
  }

}

static void MX_TIM10_Init(void)
{

  TIM_OC_InitTypeDef sConfigOC = {0};

  htim10.Instance = TIM10;
  htim10.Init.Prescaler = 29;
  htim10.Init.CounterMode = TIM_COUNTERMODE_UP;
  htim10.Init.Period = __PWMRATE;
  htim10.Init.ClockDivision = TIM_CLOCKDIVISION_DIV1;
  htim10.Init.AutoReloadPreload = TIM_AUTORELOAD_PRELOAD_DISABLE;
  if (HAL_TIM_Base_Init(&htim10) != HAL_OK)
  {
    Error_Handler();
  }
  if (HAL_TIM_PWM_Init(&htim10) != HAL_OK)
  {
    Error_Handler();
  }
  sConfigOC.OCMode = TIM_OCMODE_PWM1;
  sConfigOC.Pulse = 10;
  sConfigOC.OCPolarity = TIM_OCPOLARITY_HIGH;
  sConfigOC.OCFastMode = TIM_OCFAST_DISABLE;
  if (HAL_TIM_PWM_ConfigChannel(&htim10, &sConfigOC, TIM_CHANNEL_1) != HAL_OK)
  {
    Error_Handler();
  }
  HAL_TIM_MspPostInit(&htim10);

}

static void MX_TIM12_Init(void)
{

  TIM_ClockConfigTypeDef sClockSourceConfig = {0};
  TIM_IC_InitTypeDef sConfigIC = {0};

  htim12.Instance = TIM12;
  htim12.Init.Prescaler = 0;
  htim12.Init.CounterMode = TIM_COUNTERMODE_UP;
  htim12.Init.Period = 65535;
  htim12.Init.ClockDivision = TIM_CLOCKDIVISION_DIV1;
  htim12.Init.AutoReloadPreload = TIM_AUTORELOAD_PRELOAD_DISABLE;
  if (HAL_TIM_Base_Init(&htim12) != HAL_OK)
  {
    Error_Handler();
  }
  sClockSourceConfig.ClockSource = TIM_CLOCKSOURCE_INTERNAL;
  if (HAL_TIM_ConfigClockSource(&htim12, &sClockSourceConfig) != HAL_OK)
  {
    Error_Handler();
  }
  if (HAL_TIM_IC_Init(&htim12) != HAL_OK)
  {
    Error_Handler();
  }
  sConfigIC.ICPolarity = TIM_INPUTCHANNELPOLARITY_RISING;
  sConfigIC.ICSelection = TIM_ICSELECTION_DIRECTTI;
  sConfigIC.ICPrescaler = TIM_ICPSC_DIV1;
  sConfigIC.ICFilter = 15;
  if (HAL_TIM_IC_ConfigChannel(&htim12, &sConfigIC, TIM_CHANNEL_1) != HAL_OK)
  {
    Error_Handler();
  }
  if (HAL_TIM_IC_ConfigChannel(&htim12, &sConfigIC, TIM_CHANNEL_2) != HAL_OK)
  {
    Error_Handler();
  }

}

static void MX_USART1_UART_Init(void)
{

  huart1.Instance = USART1;
  huart1.Init.BaudRate = 921600;
  huart1.Init.WordLength = UART_WORDLENGTH_8B;
  huart1.Init.StopBits = UART_STOPBITS_1;
  huart1.Init.Parity = UART_PARITY_NONE;
  huart1.Init.Mode = UART_MODE_TX_RX;
  huart1.Init.HwFlowCtl = UART_HWCONTROL_NONE;
  huart1.Init.OverSampling = UART_OVERSAMPLING_16;
  if (HAL_UART_Init(&huart1) != HAL_OK)
  {
    Error_Handler();
  }

}

static void MX_USART3_UART_Init(void)
{

  huart3.Instance = USART3;
  huart3.Init.BaudRate = 57600;
  huart3.Init.WordLength = UART_WORDLENGTH_8B;
  huart3.Init.StopBits = UART_STOPBITS_1;
  huart3.Init.Parity = UART_PARITY_NONE;
  huart3.Init.Mode = UART_MODE_TX_RX;
  huart3.Init.HwFlowCtl = UART_HWCONTROL_NONE;
  huart3.Init.OverSampling = UART_OVERSAMPLING_16;
  if (HAL_UART_Init(&huart3) != HAL_OK)
  {
    Error_Handler();
  }

}

static void MX_DMA_Init(void)
{

  /* DMA controller clock enable */
  __HAL_RCC_DMA1_CLK_ENABLE();
  __HAL_RCC_DMA2_CLK_ENABLE();

  /* DMA interrupt init */
  /* DMA1_Stream1_IRQn interrupt configuration */
  HAL_NVIC_SetPriority(DMA1_Stream1_IRQn, 5, 0);
  HAL_NVIC_EnableIRQ(DMA1_Stream1_IRQn);
  /* DMA1_Stream3_IRQn interrupt configuration */
  HAL_NVIC_SetPriority(DMA1_Stream3_IRQn, 5, 0);
  HAL_NVIC_EnableIRQ(DMA1_Stream3_IRQn);
  /* DMA1_Stream5_IRQn interrupt configuration */
  HAL_NVIC_SetPriority(DMA1_Stream5_IRQn, 5, 0);
  HAL_NVIC_EnableIRQ(DMA1_Stream5_IRQn);
  /* DMA1_Stream6_IRQn interrupt configuration */
  HAL_NVIC_SetPriority(DMA1_Stream6_IRQn, 5, 0);
  HAL_NVIC_EnableIRQ(DMA1_Stream6_IRQn);
  /* DMA2_Stream0_IRQn interrupt configuration */
  HAL_NVIC_SetPriority(DMA2_Stream0_IRQn, 5, 0);
  HAL_NVIC_EnableIRQ(DMA2_Stream0_IRQn);
  /* DMA2_Stream1_IRQn interrupt configuration */
  HAL_NVIC_SetPriority(DMA2_Stream1_IRQn, 5, 0);
  HAL_NVIC_EnableIRQ(DMA2_Stream1_IRQn);
  /* DMA2_Stream2_IRQn interrupt configuration */
  HAL_NVIC_SetPriority(DMA2_Stream2_IRQn, 5, 0);
  HAL_NVIC_EnableIRQ(DMA2_Stream2_IRQn);
  /* DMA2_Stream5_IRQn interrupt configuration */
  HAL_NVIC_SetPriority(DMA2_Stream5_IRQn, 5, 0);
  HAL_NVIC_EnableIRQ(DMA2_Stream5_IRQn);
  /* DMA2_Stream7_IRQn interrupt configuration */
  HAL_NVIC_SetPriority(DMA2_Stream7_IRQn, 5, 0);
  HAL_NVIC_EnableIRQ(DMA2_Stream7_IRQn);

}

static void MX_GPIO_Init(void)
{
  GPIO_InitTypeDef GPIO_InitStruct = {0};

  /* GPIO Ports Clock Enable */
  __HAL_RCC_GPIOE_CLK_ENABLE();
  __HAL_RCC_GPIOC_CLK_ENABLE();
  __HAL_RCC_GPIOH_CLK_ENABLE();
  __HAL_RCC_GPIOA_CLK_ENABLE();
  __HAL_RCC_GPIOB_CLK_ENABLE();
  __HAL_RCC_GPIOD_CLK_ENABLE();

  /*Configure GPIO pin Output Level */
  HAL_GPIO_WritePin(GPIOD, FSW_DL_Pin|FSW_EC_Pin|_RED1_Pin|_GREEN1_Pin
                          |_YELLOW1_Pin|_BLUE1_Pin|_RED2_Pin|_GREEN2_Pin
                          |_YELLOW2_Pin|_BLUE2_Pin, GPIO_PIN_SET);

  /*Configure GPIO pin Output Level */
  HAL_GPIO_WritePin(cwbOVRD_GPIO_Port, cwbOVRD_Pin, GPIO_PIN_SET);

  /*Configure GPIO pin Output Level */
  HAL_GPIO_WritePin(GPIOB, _12Voff_Pin|_SYS_SHG_Pin, GPIO_PIN_RESET);

  /*Configure GPIO pins : FSW2_Pin FSW3_Pin PE4_Pin PE7_Pin
                           PE8_Pin PE10_Pin PE12_Pin PE15_Pin
                           FSW0_Pin FSW1_Pin */
  GPIO_InitStruct.Pin = FSW2_Pin|FSW3_Pin|PE4_Pin|PE7_Pin
                          |PE8_Pin|PE10_Pin|PE12_Pin|PE15_Pin
                          |FSW0_Pin|FSW1_Pin;
  GPIO_InitStruct.Mode = GPIO_MODE_INPUT;
  GPIO_InitStruct.Pull = GPIO_PULLUP;
  HAL_GPIO_Init(GPIOE, &GPIO_InitStruct);

  /*Configure GPIO pins : cwbBUTTON_Pin cwbDOOR_Pin cwbENGM_Pin */
  GPIO_InitStruct.Pin = cwbBUTTON_Pin|cwbDOOR_Pin|cwbENGM_Pin;
  GPIO_InitStruct.Mode = GPIO_MODE_INPUT;
  GPIO_InitStruct.Pull = GPIO_PULLDOWN;
  HAL_GPIO_Init(GPIOD, &GPIO_InitStruct);

  /*Configure GPIO pins : FSW_DL_Pin FSW_EC_Pin _RED1_Pin _GREEN1_Pin
                           _YELLOW1_Pin _BLUE1_Pin _RED2_Pin _GREEN2_Pin
                           _YELLOW2_Pin _BLUE2_Pin */
  GPIO_InitStruct.Pin = FSW_DL_Pin|FSW_EC_Pin|_RED1_Pin|_GREEN1_Pin
                          |_YELLOW1_Pin|_BLUE1_Pin|_RED2_Pin|_GREEN2_Pin
                          |_YELLOW2_Pin|_BLUE2_Pin;
  GPIO_InitStruct.Mode = GPIO_MODE_OUTPUT_OD;
  GPIO_InitStruct.Pull = GPIO_NOPULL;
  GPIO_InitStruct.Speed = GPIO_SPEED_FREQ_LOW;
  HAL_GPIO_Init(GPIOD, &GPIO_InitStruct);

  /*Configure GPIO pin : cwbOVRD_Pin */
  GPIO_InitStruct.Pin = cwbOVRD_Pin;
  GPIO_InitStruct.Mode = GPIO_MODE_OUTPUT_OD;
  GPIO_InitStruct.Pull = GPIO_NOPULL;
  GPIO_InitStruct.Speed = GPIO_SPEED_FREQ_LOW;
  HAL_GPIO_Init(cwbOVRD_GPIO_Port, &GPIO_InitStruct);

  /*Configure GPIO pin : _12Voff_Pin */
  GPIO_InitStruct.Pin = _12Voff_Pin;
  GPIO_InitStruct.Mode = GPIO_MODE_OUTPUT_PP;
  GPIO_InitStruct.Pull = GPIO_NOPULL;
  GPIO_InitStruct.Speed = GPIO_SPEED_FREQ_LOW;
  HAL_GPIO_Init(_12Voff_GPIO_Port, &GPIO_InitStruct);

  /*Configure GPIO pin : _SYS_SHG_Pin */
  GPIO_InitStruct.Pin = _SYS_SHG_Pin;
  GPIO_InitStruct.Mode = GPIO_MODE_OUTPUT_OD;
  GPIO_InitStruct.Pull = GPIO_NOPULL;
  GPIO_InitStruct.Speed = GPIO_SPEED_FREQ_LOW;
  HAL_GPIO_Init(_SYS_SHG_GPIO_Port, &GPIO_InitStruct);

}

/* USER CODE BEGIN 4 */
SemaphoreHandle_t sWait;
TaskHandle_t 			*pWait;
//___________________________________________________________________________
void	_wait(int t) {
			_io *temp=_stdio(NULL);
			if(*pWait==NULL)
				xTaskCreate((TaskFunction_t)_task, "---", 512, NULL, 0, pWait);
			++pWait;
			xSemaphoreGive(sWait);
			taskYIELD();
			vTaskDelay(t);
			xSemaphoreTake(sWait,portMAX_DELAY);
			--pWait;
			_stdio(temp);
}
//___________________________________________________________________________
void	_task(const void *t) {
			while(1) {
				if(xSemaphoreTake(sWait,portMAX_DELAY)) {
					Watchdog();
					_proc_loop();
					xSemaphoreGive(sWait);
				}
				taskYIELD();
			}
}
//___________________________________________________________________________
/* USER CODE END 4 */

void StartDefaultTask(void const * argument)
{
  /* init code for USB_DEVICE */
  MX_USB_DEVICE_Init();
  /* USER CODE BEGIN 5 */
  /* Infinite loop */
	makeIoc();
	sWait=xSemaphoreCreateMutex();
	pWait=calloc(16,sizeof(TaskHandle_t));
	xTaskCreate((TaskFunction_t)_task, "---", 512, NULL, 0, pWait++);
  for(;;)
  {
    osDelay(1);
  }
  /* USER CODE END 5 */
}

void HAL_TIM_PeriodElapsedCallback(TIM_HandleTypeDef *htim)
{
  /* USER CODE BEGIN Callback 0 */
  if (htim->Instance == TIM2) {
    pollLed();
  }
  /* USER CODE END Callback 0 */
  if (htim->Instance == TIM2) {
    HAL_IncTick();
  }
  /* USER CODE BEGIN Callback 1 */
  if (htim->Instance == TIM2) {
		TIM10->CCR1=fan_drive;
		for(int i=0; i<__VALVES; ++i)
			if(valve_timeout[i] && HAL_GetTick() > valve_timeout[i]) {
				valve_timeout[i]=0;
				if(valve_drive[i])
					valve_drive[i]=0;
				else
					valve_drive[i]=__PWMRATE;
			}
	}
  /* USER CODE END Callback 1 */
}

void Error_Handler(void)
{
  while(1)
  {
  }
}

/************************ (C) COPYRIGHT STMicroelectronics *****END OF FILE****/

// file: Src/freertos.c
/* USER CODE BEGIN Header */
/**
  ******************************************************************************
  * File Name          : freertos.c
  * Description        : Code for freertos applications
  ******************************************************************************
  * This notice applies to any and all portions of this file
  * that are not between comment pairs USER CODE BEGIN and
  * USER CODE END. Other portions of this file, whether
  * inserted by the user or by software development tools
  * are owned by their respective copyright owners.
  *
  * Copyright (c) 2019 STMicroelectronics International N.V.
  * All rights reserved.
  *
  * Redistribution and use in source and binary forms, with or without
  * modification, are permitted, provided that the following conditions are met:
  *
  * 1. Redistribution of source code must retain the above copyright notice,
  *    this list of conditions and the following disclaimer.
  * 2. Redistributions in binary form must reproduce the above copyright notice,
  *    this list of conditions and the following disclaimer in the documentation
  *    and/or other materials provided with the distribution.
  * 3. Neither the name of STMicroelectronics nor the names of other
  *    contributors to this software may be used to endorse or promote products
  *    derived from this software without specific written permission.
  * 4. This software, including modifications and/or derivative works of this
  *    software, must execute solely and exclusively on microcontroller or
  *    microprocessor devices manufactured by or for STMicroelectronics.
  * 5. Redistribution and use of this software other than as permitted under
  *    this license is void and will automatically terminate your rights under
  *    this license.
  *
  * THIS SOFTWARE IS PROVIDED BY STMICROELECTRONICS AND CONTRIBUTORS "AS IS"
  * AND ANY EXPRESS, IMPLIED OR STATUTORY WARRANTIES, INCLUDING, BUT NOT
  * LIMITED TO, THE IMPLIED WARRANTIES OF MERCHANTABILITY, FITNESS FOR A
  * PARTICULAR PURPOSE AND NON-INFRINGEMENT OF THIRD PARTY INTELLECTUAL PROPERTY
  * RIGHTS ARE DISCLAIMED TO THE FULLEST EXTENT PERMITTED BY LAW. IN NO EVENT
  * SHALL STMICROELECTRONICS OR CONTRIBUTORS BE LIABLE FOR ANY DIRECT, INDIRECT,
  * INCIDENTAL, SPECIAL, EXEMPLARY, OR CONSEQUENTIAL DAMAGES (INCLUDING, BUT NOT
  * LIMITED TO, PROCUREMENT OF SUBSTITUTE GOODS OR SERVICES; LOSS OF USE, DATA,
  * OR PROFITS; OR BUSINESS INTERRUPTION) HOWEVER CAUSED AND ON ANY THEORY OF
  * LIABILITY, WHETHER IN CONTRACT, STRICT LIABILITY, OR TORT (INCLUDING
  * NEGLIGENCE OR OTHERWISE) ARISING IN ANY WAY OUT OF THE USE OF THIS SOFTWARE,
  * EVEN IF ADVISED OF THE POSSIBILITY OF SUCH DAMAGE.
  *
  ******************************************************************************
  */
/* USER CODE END Header */

#include "FreeRTOS.h"
#include "task.h"
#include "main.h"

/* GetIdleTaskMemory prototype (linked to static allocation support) */
void vApplicationGetIdleTaskMemory( StaticTask_t **ppxIdleTaskTCBBuffer, StackType_t **ppxIdleTaskStackBuffer, uint32_t *pulIdleTaskStackSize );

/* Hook prototypes */
void vApplicationStackOverflowHook(xTaskHandle xTask, signed char *pcTaskName);
void vApplicationMallocFailedHook(void);

/* USER CODE BEGIN 4 */
__weak void vApplicationStackOverflowHook(xTaskHandle xTask, signed char *pcTaskName)
{
   /* Run time stack overflow checking is performed if
   configCHECK_FOR_STACK_OVERFLOW is defined to 1 or 2. This hook function is
   called if a stack overflow is detected. */
}
/* USER CODE END 4 */

/* USER CODE BEGIN 5 */
__weak void vApplicationMallocFailedHook(void)
{
   /* vApplicationMallocFailedHook() will only be called if
   configUSE_MALLOC_FAILED_HOOK is set to 1 in FreeRTOSConfig.h. It is a hook
   function that will get called if a call to pvPortMalloc() fails.
   pvPortMalloc() is called internally by the kernel whenever a task, queue,
   timer or semaphore is created. It is also called by various parts of the
   demo application. If heap_1.c or heap_2.c are used, then the size of the
   heap available to pvPortMalloc() is defined by configTOTAL_HEAP_SIZE in
   FreeRTOSConfig.h, and the xPortGetFreeHeapSize() API function can be used
   to query the size of free heap space that remains (although it does not
   provide information on how the remaining heap might be fragmented). */
}
/* USER CODE END 5 */

/* USER CODE BEGIN GET_IDLE_TASK_MEMORY */
static StaticTask_t xIdleTaskTCBBuffer;
static StackType_t xIdleStack[configMINIMAL_STACK_SIZE];

void vApplicationGetIdleTaskMemory( StaticTask_t **ppxIdleTaskTCBBuffer, StackType_t **ppxIdleTaskStackBuffer, uint32_t *pulIdleTaskStackSize )
{
  *ppxIdleTaskTCBBuffer = &xIdleTaskTCBBuffer;
  *ppxIdleTaskStackBuffer = &xIdleStack[0];
  *pulIdleTaskStackSize = configMINIMAL_STACK_SIZE;
  /* place for user code */
}
/* USER CODE END GET_IDLE_TASK_MEMORY */

/************************ (C) COPYRIGHT STMicroelectronics *****END OF FILE****/
